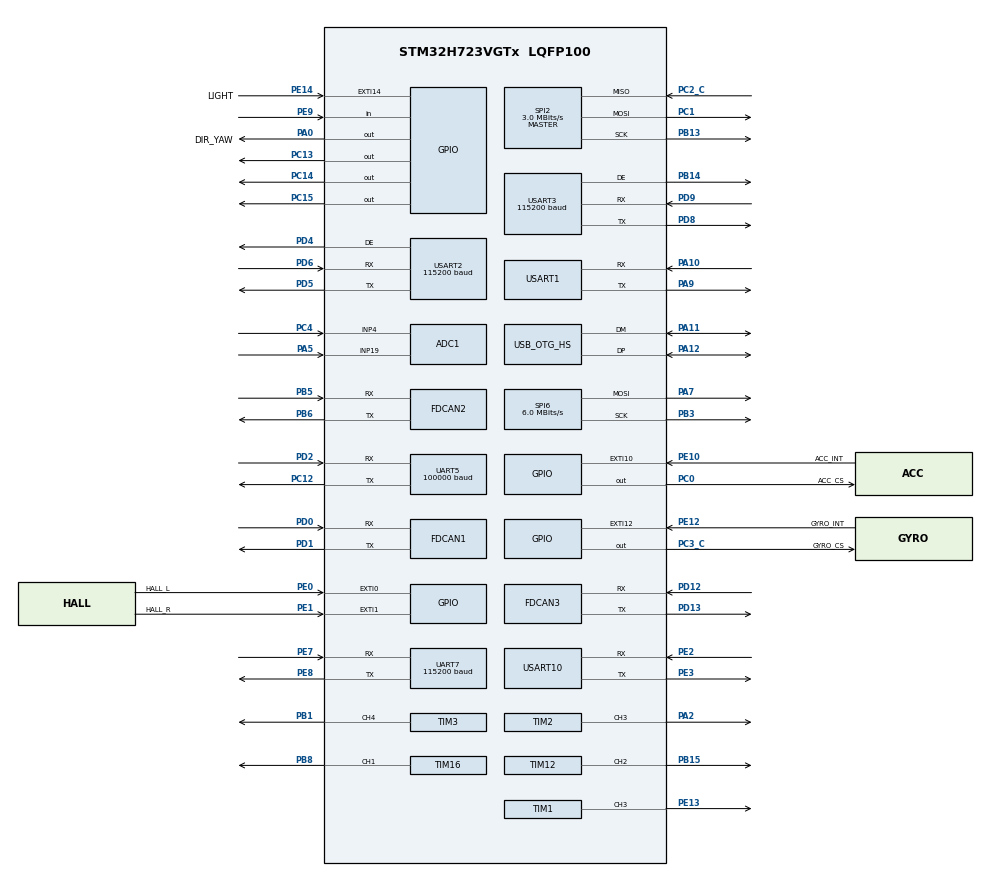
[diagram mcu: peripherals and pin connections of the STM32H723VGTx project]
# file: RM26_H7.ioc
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ADC1.Channel-0\#ChannelRegularConversion=ADC_CHANNEL_4
ADC1.NbrOfConversionFlag=1
ADC1.OffsetNumber-0\#ChannelRegularConversion=ADC_OFFSET_NONE
ADC1.OffsetSignedSaturation-0\#ChannelRegularConversion=DISABLE
ADC1.Rank-0\#ChannelRegularConversion=1
ADC1.SamplingTime-0\#ChannelRegularConversion=ADC_SAMPLETIME_1CYCLE_5
ADC1.master=1
CORTEX_M7.AccessPermission_Spec=MPU_REGION_FULL_ACCESS
CORTEX_M7.BaseAddress_Spec=0x24000000
CORTEX_M7.CPU_DCache=Enabled
CORTEX_M7.CPU_ICache=Enabled
CORTEX_M7.DisableExec_Spec=MPU_INSTRUCTION_ACCESS_ENABLE
CORTEX_M7.IsShareable_Spec=MPU_ACCESS_SHAREABLE
CORTEX_M7.MPU_Control=__NULL
CORTEX_M7.Size_Spec=MPU_REGION_SIZE_512KB
CORTEX_M7.SubRegionDisable_Spec=0x0
CORTEX_M7.TypeExtField_Spec=MPU_TEX_LEVEL1
CORTEX_M7.default_mode_Activation=0
Dma.Request0=USART1_RX
Dma.Request1=USART1_TX
Dma.Request10=USART3_TX
Dma.Request2=UART7_RX
Dma.Request3=UART7_TX
Dma.Request4=UART5_RX
Dma.Request5=USART10_RX
Dma.Request6=USART10_TX
Dma.Request7=USART2_RX
Dma.Request8=USART2_TX
Dma.Request9=USART3_RX
Dma.UART5_RX.4.Direction=DMA_PERIPH_TO_MEMORY
Dma.UART5_RX.4.EventEnable=DISABLE
Dma.UART5_RX.4.FIFOMode=DMA_FIFOMODE_DISABLE
Dma.UART5_RX.4.Instance=DMA2_Stream3
Dma.UART5_RX.4.MemDataAlignment=DMA_MDATAALIGN_BYTE
Dma.UART5_RX.4.MemInc=DMA_MINC_ENABLE
Dma.UART5_RX.4.Mode=DMA_CIRCULAR
Dma.UART5_RX.4.PeriphDataAlignment=DMA_PDATAALIGN_BYTE
Dma.UART5_RX.4.PeriphInc=DMA_PINC_DISABLE
Dma.UART5_RX.4.Polarity=HAL_DMAMUX_REQ_GEN_RISING
Dma.UART5_RX.4.Priority=DMA_PRIORITY_VERY_HIGH
Dma.UART5_RX.4.RequestNumber=1
Dma.UART5_RX.4.SignalID=NONE
Dma.UART5_RX.4.SyncEnable=DISABLE
Dma.UART5_RX.4.SyncPolarity=HAL_DMAMUX_SYNC_NO_EVENT
Dma.UART5_RX.4.SyncRequestNumber=1
Dma.UART5_RX.4.SyncSignalID=NONE
Dma.UART7_RX.2.Direction=DMA_PERIPH_TO_MEMORY
Dma.UART7_RX.2.EventEnable=DISABLE
Dma.UART7_RX.2.FIFOMode=DMA_FIFOMODE_DISABLE
Dma.UART7_RX.2.Instance=DMA1_Stream2
Dma.UART7_RX.2.MemDataAlignment=DMA_MDATAALIGN_BYTE
Dma.UART7_RX.2.MemInc=DMA_MINC_ENABLE
Dma.UART7_RX.2.Mode=DMA_CIRCULAR
Dma.UART7_RX.2.PeriphDataAlignment=DMA_PDATAALIGN_BYTE
Dma.UART7_RX.2.PeriphInc=DMA_PINC_DISABLE
Dma.UART7_RX.2.Polarity=HAL_DMAMUX_REQ_GEN_RISING
Dma.UART7_RX.2.Priority=DMA_PRIORITY_VERY_HIGH
Dma.UART7_RX.2.RequestNumber=1
Dma.UART7_RX.2.SignalID=NONE
Dma.UART7_RX.2.SyncEnable=DISABLE
Dma.UART7_RX.2.SyncPolarity=HAL_DMAMUX_SYNC_NO_EVENT
Dma.UART7_RX.2.SyncRequestNumber=1
Dma.UART7_RX.2.SyncSignalID=NONE
Dma.UART7_TX.3.Direction=DMA_MEMORY_TO_PERIPH
Dma.UART7_TX.3.EventEnable=DISABLE
Dma.UART7_TX.3.FIFOMode=DMA_FIFOMODE_DISABLE
Dma.UART7_TX.3.Instance=DMA1_Stream3
Dma.UART7_TX.3.MemDataAlignment=DMA_MDATAALIGN_BYTE
Dma.UART7_TX.3.MemInc=DMA_MINC_ENABLE
Dma.UART7_TX.3.Mode=DMA_CIRCULAR
Dma.UART7_TX.3.PeriphDataAlignment=DMA_PDATAALIGN_BYTE
Dma.UART7_TX.3.PeriphInc=DMA_PINC_DISABLE
Dma.UART7_TX.3.Polarity=HAL_DMAMUX_REQ_GEN_RISING
Dma.UART7_TX.3.Priority=DMA_PRIORITY_VERY_HIGH
Dma.UART7_TX.3.RequestNumber=1
Dma.UART7_TX.3.SignalID=NONE
Dma.UART7_TX.3.SyncEnable=DISABLE
Dma.UART7_TX.3.SyncPolarity=HAL_DMAMUX_SYNC_NO_EVENT
Dma.UART7_TX.3.SyncRequestNumber=1
Dma.UART7_TX.3.SyncSignalID=NONE
Dma.USART10_RX.5.Direction=DMA_PERIPH_TO_MEMORY
Dma.USART10_RX.5.EventEnable=DISABLE
Dma.USART10_RX.5.FIFOMode=DMA_FIFOMODE_DISABLE
Dma.USART10_RX.5.Instance=DMA1_Stream6
Dma.USART10_RX.5.MemDataAlignment=DMA_MDATAALIGN_BYTE
Dma.USART10_RX.5.MemInc=DMA_MINC_ENABLE
Dma.USART10_RX.5.Mode=DMA_NORMAL
Dma.USART10_RX.5.PeriphDataAlignment=DMA_PDATAALIGN_BYTE
Dma.USART10_RX.5.PeriphInc=DMA_PINC_DISABLE
Dma.USART10_RX.5.Polarity=HAL_DMAMUX_REQ_GEN_RISING
Dma.USART10_RX.5.Priority=DMA_PRIORITY_LOW
Dma.USART10_RX.5.RequestNumber=1
Dma.USART10_RX.5.SignalID=NONE
Dma.USART10_RX.5.SyncEnable=DISABLE
Dma.USART10_RX.5.SyncPolarity=HAL_DMAMUX_SYNC_NO_EVENT
Dma.USART10_RX.5.SyncRequestNumber=1
Dma.USART10_RX.5.SyncSignalID=NONE
Dma.USART10_TX.6.Direction=DMA_MEMORY_TO_PERIPH
Dma.USART10_TX.6.EventEnable=DISABLE
Dma.USART10_TX.6.FIFOMode=DMA_FIFOMODE_DISABLE
Dma.USART10_TX.6.Instance=DMA1_Stream7
Dma.USART10_TX.6.MemDataAlignment=DMA_MDATAALIGN_BYTE
Dma.USART10_TX.6.MemInc=DMA_MINC_ENABLE
Dma.USART10_TX.6.Mode=DMA_NORMAL
Dma.USART10_TX.6.PeriphDataAlignment=DMA_PDATAALIGN_BYTE
Dma.USART10_TX.6.PeriphInc=DMA_PINC_DISABLE
Dma.USART10_TX.6.Polarity=HAL_DMAMUX_REQ_GEN_RISING
Dma.USART10_TX.6.Priority=DMA_PRIORITY_LOW
Dma.USART10_TX.6.RequestNumber=1
Dma.USART10_TX.6.SignalID=NONE
Dma.USART10_TX.6.SyncEnable=DISABLE
Dma.USART10_TX.6.SyncPolarity=HAL_DMAMUX_SYNC_NO_EVENT
Dma.USART10_TX.6.SyncRequestNumber=1
Dma.USART10_TX.6.SyncSignalID=NONE
Dma.USART1_RX.0.Direction=DMA_PERIPH_TO_MEMORY
Dma.USART1_RX.0.EventEnable=DISABLE
Dma.USART1_RX.0.FIFOMode=DMA_FIFOMODE_DISABLE
Dma.USART1_RX.0.Instance=DMA1_Stream4
Dma.USART1_RX.0.MemDataAlignment=DMA_MDATAALIGN_BYTE
Dma.USART1_RX.0.MemInc=DMA_MINC_ENABLE
Dma.USART1_RX.0.Mode=DMA_CIRCULAR
Dma.USART1_RX.0.PeriphDataAlignment=DMA_PDATAALIGN_BYTE
Dma.USART1_RX.0.PeriphInc=DMA_PINC_DISABLE
Dma.USART1_RX.0.Polarity=HAL_DMAMUX_REQ_GEN_RISING
Dma.USART1_RX.0.Priority=DMA_PRIORITY_VERY_HIGH
Dma.USART1_RX.0.RequestNumber=1
Dma.USART1_RX.0.SignalID=NONE
Dma.USART1_RX.0.SyncEnable=DISABLE
Dma.USART1_RX.0.SyncPolarity=HAL_DMAMUX_SYNC_NO_EVENT
Dma.USART1_RX.0.SyncRequestNumber=1
Dma.USART1_RX.0.SyncSignalID=NONE
Dma.USART1_TX.1.Direction=DMA_MEMORY_TO_PERIPH
Dma.USART1_TX.1.EventEnable=DISABLE
Dma.USART1_TX.1.FIFOMode=DMA_FIFOMODE_DISABLE
Dma.USART1_TX.1.Instance=DMA1_Stream5
Dma.USART1_TX.1.MemDataAlignment=DMA_MDATAALIGN_BYTE
Dma.USART1_TX.1.MemInc=DMA_MINC_ENABLE
Dma.USART1_TX.1.Mode=DMA_NORMAL
Dma.USART1_TX.1.PeriphDataAlignment=DMA_PDATAALIGN_BYTE
Dma.USART1_TX.1.PeriphInc=DMA_PINC_DISABLE
Dma.USART1_TX.1.Polarity=HAL_DMAMUX_REQ_GEN_RISING
Dma.USART1_TX.1.Priority=DMA_PRIORITY_VERY_HIGH
Dma.USART1_TX.1.RequestNumber=1
Dma.USART1_TX.1.SignalID=NONE
Dma.USART1_TX.1.SyncEnable=DISABLE
Dma.USART1_TX.1.SyncPolarity=HAL_DMAMUX_SYNC_NO_EVENT
Dma.USART1_TX.1.SyncRequestNumber=1
Dma.USART1_TX.1.SyncSignalID=NONE
Dma.USART2_RX.7.Direction=DMA_PERIPH_TO_MEMORY
Dma.USART2_RX.7.EventEnable=DISABLE
Dma.USART2_RX.7.FIFOMode=DMA_FIFOMODE_DISABLE
Dma.USART2_RX.7.Instance=DMA1_Stream0
Dma.USART2_RX.7.MemDataAlignment=DMA_MDATAALIGN_BYTE
Dma.USART2_RX.7.MemInc=DMA_MINC_ENABLE
Dma.USART2_RX.7.Mode=DMA_NORMAL
Dma.USART2_RX.7.PeriphDataAlignment=DMA_PDATAALIGN_BYTE
Dma.USART2_RX.7.PeriphInc=DMA_PINC_DISABLE
Dma.USART2_RX.7.Polarity=HAL_DMAMUX_REQ_GEN_RISING
Dma.USART2_RX.7.Priority=DMA_PRIORITY_LOW
Dma.USART2_RX.7.RequestNumber=1
Dma.USART2_RX.7.SignalID=NONE
Dma.USART2_RX.7.SyncEnable=DISABLE
Dma.USART2_RX.7.SyncPolarity=HAL_DMAMUX_SYNC_NO_EVENT
Dma.USART2_RX.7.SyncRequestNumber=1
Dma.USART2_RX.7.SyncSignalID=NONE
Dma.USART2_TX.8.Direction=DMA_MEMORY_TO_PERIPH
Dma.USART2_TX.8.EventEnable=DISABLE
Dma.USART2_TX.8.FIFOMode=DMA_FIFOMODE_DISABLE
Dma.USART2_TX.8.Instance=DMA1_Stream1
Dma.USART2_TX.8.MemDataAlignment=DMA_MDATAALIGN_BYTE
Dma.USART2_TX.8.MemInc=DMA_MINC_ENABLE
Dma.USART2_TX.8.Mode=DMA_NORMAL
Dma.USART2_TX.8.PeriphDataAlignment=DMA_PDATAALIGN_BYTE
Dma.USART2_TX.8.PeriphInc=DMA_PINC_DISABLE
Dma.USART2_TX.8.Polarity=HAL_DMAMUX_REQ_GEN_RISING
Dma.USART2_TX.8.Priority=DMA_PRIORITY_LOW
Dma.USART2_TX.8.RequestNumber=1
Dma.USART2_TX.8.SignalID=NONE
Dma.USART2_TX.8.SyncEnable=DISABLE
Dma.USART2_TX.8.SyncPolarity=HAL_DMAMUX_SYNC_NO_EVENT
Dma.USART2_TX.8.SyncRequestNumber=1
Dma.USART2_TX.8.SyncSignalID=NONE
Dma.USART3_RX.9.Direction=DMA_PERIPH_TO_MEMORY
Dma.USART3_RX.9.EventEnable=DISABLE
Dma.USART3_RX.9.FIFOMode=DMA_FIFOMODE_DISABLE
Dma.USART3_RX.9.Instance=DMA2_Stream7
Dma.USART3_RX.9.MemDataAlignment=DMA_MDATAALIGN_BYTE
Dma.USART3_RX.9.MemInc=DMA_MINC_ENABLE
Dma.USART3_RX.9.Mode=DMA_NORMAL
Dma.USART3_RX.9.PeriphDataAlignment=DMA_PDATAALIGN_BYTE
Dma.USART3_RX.9.PeriphInc=DMA_PINC_DISABLE
Dma.USART3_RX.9.Polarity=HAL_DMAMUX_REQ_GEN_RISING
Dma.USART3_RX.9.Priority=DMA_PRIORITY_LOW
Dma.USART3_RX.9.RequestNumber=1
Dma.USART3_RX.9.SignalID=NONE
Dma.USART3_RX.9.SyncEnable=DISABLE
Dma.USART3_RX.9.SyncPolarity=HAL_DMAMUX_SYNC_NO_EVENT
Dma.USART3_RX.9.SyncRequestNumber=1
Dma.USART3_RX.9.SyncSignalID=NONE
Dma.USART3_TX.10.Direction=DMA_MEMORY_TO_PERIPH
Dma.USART3_TX.10.EventEnable=DISABLE
Dma.USART3_TX.10.FIFOMode=DMA_FIFOMODE_DISABLE
Dma.USART3_TX.10.Instance=DMA2_Stream6
Dma.USART3_TX.10.MemDataAlignment=DMA_MDATAALIGN_BYTE
Dma.USART3_TX.10.MemInc=DMA_MINC_ENABLE
Dma.USART3_TX.10.Mode=DMA_NORMAL
Dma.USART3_TX.10.PeriphDataAlignment=DMA_PDATAALIGN_BYTE
Dma.USART3_TX.10.PeriphInc=DMA_PINC_DISABLE
Dma.USART3_TX.10.Polarity=HAL_DMAMUX_REQ_GEN_RISING
Dma.USART3_TX.10.Priority=DMA_PRIORITY_LOW
Dma.USART3_TX.10.RequestNumber=1
Dma.USART3_TX.10.SignalID=NONE
Dma.USART3_TX.10.SyncEnable=DISABLE
Dma.USART3_TX.10.SyncPolarity=HAL_DMAMUX_SYNC_NO_EVENT
Dma.USART3_TX.10.SyncRequestNumber=1
Dma.USART3_TX.10.SyncSignalID=NONE
FDCAN1.CalculateBaudRateNominal=1000000
FDCAN1.CalculateTimeBitNominal=1000
FDCAN1.CalculateTimeQuantumNominal=166.66666666666666
FDCAN1.DataPrescaler=4
FDCAN1.DataSyncJumpWidth=1
FDCAN1.DataTimeSeg1=3
FDCAN1.DataTimeSeg2=2
FDCAN1.NominalPrescaler=4
FDCAN1.NominalSyncJumpWidth=1
FDCAN1.NominalTimeSeg1=3
FDCAN1.NominalTimeSeg2=2
FDCAN1.ProtocolException=ENABLE
FDCAN1.RxFifo0ElmtsNbr=4
FDCAN1.StdFiltersNbr=1
FDCAN1.TxEventsNbr=0
FDCAN1.TxFifoQueueElmtsNbr=2
FDCAN2.CalculateBaudRateNominal=1000000
FDCAN2.CalculateTimeBitNominal=1000
FDCAN2.CalculateTimeQuantumNominal=166.66666666666666
FDCAN2.DataPrescaler=4
FDCAN2.DataSyncJumpWidth=1
FDCAN2.DataTimeSeg1=3
FDCAN2.DataTimeSeg2=2
FDCAN2.MessageRAMOffset=853
FDCAN2.NominalPrescaler=4
FDCAN2.NominalSyncJumpWidth=1
FDCAN2.NominalTimeSeg1=3
FDCAN2.NominalTimeSeg2=2
FDCAN2.ProtocolException=ENABLE
FDCAN2.RxFifo0ElmtsNbr=8
FDCAN2.StdFiltersNbr=1
FDCAN2.TxFifoQueueElmtsNbr=8
FDCAN3.CalculateBaudRateNominal=1000000
FDCAN3.CalculateTimeBitNominal=1000
FDCAN3.CalculateTimeQuantumNominal=166.66666666666666
FDCAN3.DataPrescaler=4
FDCAN3.DataSyncJumpWidth=1
FDCAN3.DataTimeSeg1=3
FDCAN3.DataTimeSeg2=2
FDCAN3.ExtFiltersNbr=1
FDCAN3.MessageRAMOffset=1706
FDCAN3.NominalPrescaler=4
FDCAN3.NominalSyncJumpWidth=1
FDCAN3.NominalTimeSeg1=3
FDCAN3.NominalTimeSeg2=2
FDCAN3.ProtocolException=ENABLE
FDCAN3.RxFifo0ElmtsNbr=16
FDCAN3.StdFiltersNbr=1
FDCAN3.TxFifoQueueElmtsNbr=16
Mcu.Family=STM32H7
Mcu.Name=STM32H723VGTx
Mcu.Package=LQFP100
NVIC.DMA1_Stream0_IRQn=true\:0\:0\:false\:false\:true\:true\:false\:true\:true
NVIC.DMA1_Stream1_IRQn=true\:0\:0\:false\:false\:true\:true\:false\:true\:true
NVIC.DMA1_Stream2_IRQn=true\:0\:0\:false\:false\:true\:false\:false\:true\:true
NVIC.DMA1_Stream3_IRQn=true\:0\:0\:false\:false\:true\:false\:false\:true\:true
NVIC.DMA1_Stream4_IRQn=true\:0\:0\:false\:false\:true\:false\:false\:true\:true
NVIC.DMA1_Stream5_IRQn=true\:0\:0\:false\:false\:true\:false\:false\:true\:true
NVIC.DMA1_Stream6_IRQn=true\:0\:0\:false\:false\:true\:true\:false\:true\:true
NVIC.DMA1_Stream7_IRQn=true\:0\:0\:false\:false\:true\:true\:false\:true\:true
NVIC.DMA2_Stream3_IRQn=true\:0\:0\:false\:false\:true\:false\:false\:true\:true
NVIC.DMA2_Stream6_IRQn=true\:0\:0\:false\:false\:true\:false\:false\:true\:true
NVIC.DMA2_Stream7_IRQn=true\:0\:0\:false\:false\:true\:false\:false\:true\:true
NVIC.EXTI0_IRQn=true\:0\:0\:false\:false\:true\:false\:true\:true\:true
NVIC.EXTI15_10_IRQn=true\:0\:0\:false\:false\:true\:false\:true\:true\:true
NVIC.EXTI1_IRQn=true\:0\:0\:false\:false\:true\:false\:true\:true\:true
NVIC.FDCAN1_IT0_IRQn=true\:0\:0\:false\:false\:true\:false\:true\:true\:true
NVIC.FDCAN2_IT0_IRQn=true\:0\:0\:false\:false\:true\:false\:true\:true\:true
NVIC.FDCAN3_IT0_IRQn=true\:0\:0\:false\:false\:true\:false\:true\:true\:true
NVIC.OTG_HS_IRQn=true\:0\:0\:false\:false\:true\:false\:true\:true\:true
NVIC.PriorityGroup=NVIC_PRIORITYGROUP_4
NVIC.TIM23_IRQn=true\:15\:0\:false\:false\:true\:false\:false\:true\:true
NVIC.TIM2_IRQn=true\:0\:0\:false\:false\:true\:false\:true\:true\:true
NVIC.TIM5_IRQn=true\:0\:0\:false\:false\:true\:false\:true\:true\:true
NVIC.TimeBase=TIM23_IRQn
NVIC.TimeBaseIP=TIM23
NVIC.UART5_IRQn=true\:0\:0\:false\:false\:true\:false\:true\:true\:true
NVIC.UART7_IRQn=true\:0\:0\:false\:false\:true\:false\:true\:true\:true
NVIC.USART10_IRQn=true\:0\:0\:false\:false\:true\:false\:true\:true\:true
NVIC.USART1_IRQn=true\:0\:0\:false\:false\:true\:false\:true\:true\:true
NVIC.USART2_IRQn=true\:0\:0\:false\:false\:true\:false\:true\:true\:true
NVIC.USART3_IRQn=true\:0\:0\:false\:false\:true\:false\:true\:true\:true
PA0.GPIO_Label=DIR_YAW
PA0.GPIO_ModeDefaultOutputPP=GPIO_MODE_OUTPUT_OD
PA0.GPIO_PuPd=GPIO_NOPULL
PA0.Signal=GPIO_Output
PA10.Mode=Asynchronous
PA10.Signal=USART1_RX
PA11.Mode=Device_Only_FS
PA11.Signal=USB_OTG_HS_DM
PA12.Mode=Device_Only_FS
PA12.Signal=USB_OTG_HS_DP
PA2.Signal=S_TIM2_CH3
PA5.Signal=ADCx_INP19
PA7.Mode=TX_Only_Simplex_Unidirect_Master
PA7.Signal=SPI6_MOSI
PA9.Mode=Asynchronous
PA9.Signal=USART1_TX
PB1.Signal=S_TIM3_CH4
PB13.GPIO_Speed=GPIO_SPEED_FREQ_VERY_HIGH
PB13.Mode=Full_Duplex_Master
PB13.Signal=SPI2_SCK
PB14.Mode=Hardware Flow Control (RS485)
PB14.Signal=USART3_DE
PB15.Signal=S_TIM12_CH2
PB3(JTDO/TRACESWO).Mode=TX_Only_Simplex_Unidirect_Master
PB3(JTDO/TRACESWO).Signal=SPI6_SCK
PB5.Mode=FDCAN_Activate
PB5.Signal=FDCAN2_RX
PB6.Mode=FDCAN_Activate
PB6.Signal=FDCAN2_TX
PB8.Signal=S_TIM16_CH1
PC0.GPIO_Label=ACC_CS
PC0.GPIO_Speed=GPIO_SPEED_FREQ_VERY_HIGH
PC0.PinState=GPIO_PIN_SET
PC0.Signal=GPIO_Output
PC1.GPIO_Speed=GPIO_SPEED_FREQ_VERY_HIGH
PC1.Mode=Full_Duplex_Master
PC1.Signal=SPI2_MOSI
PC12.Mode=Asynchronous
PC12.Signal=UART5_TX
PC13.PinState=GPIO_PIN_SET
PC13.Signal=GPIO_Output
PC14-OSC32_IN.PinState=GPIO_PIN_SET
PC14-OSC32_IN.Signal=GPIO_Output
PC15-OSC32_OUT.PinState=GPIO_PIN_SET
PC15-OSC32_OUT.Signal=GPIO_Output
PC2_C.GPIO_Speed=GPIO_SPEED_FREQ_VERY_HIGH
PC2_C.Mode=Full_Duplex_Master
PC2_C.Signal=SPI2_MISO
PC3_C.GPIO_Label=GYRO_CS
PC3_C.GPIO_Speed=GPIO_SPEED_FREQ_VERY_HIGH
PC3_C.PinState=GPIO_PIN_SET
PC3_C.Signal=GPIO_Output
PC4.Signal=ADCx_INP4
PD0.Mode=FDCAN_Activate
PD0.Signal=FDCAN1_RX
PD1.Mode=FDCAN_Activate
PD1.Signal=FDCAN1_TX
PD12.Mode=FDCAN_Activate
PD12.Signal=FDCAN3_RX
PD13.Mode=FDCAN_Activate
PD13.Signal=FDCAN3_TX
PD2.GPIO_Speed=GPIO_SPEED_FREQ_LOW
PD2.Mode=Asynchronous
PD2.Signal=UART5_RX
PD4.Mode=Hardware Flow Control (RS485)
PD4.Signal=USART2_DE
PD5.Mode=Asynchronous
PD5.Signal=USART2_TX
PD6.Mode=Asynchronous
PD6.Signal=USART2_RX
PD8.Mode=Asynchronous
PD8.Signal=USART3_TX
PD9.Mode=Asynchronous
PD9.Signal=USART3_RX
PE0.GPIO_Label=HALL_L
PE0.GPIO_ModeDefaultEXTI=GPIO_MODE_IT_FALLING
PE0.GPIO_PuPd=GPIO_PULLUP
PE0.Signal=GPXTI0
PE1.GPIO_Label=HALL_R
PE1.GPIO_ModeDefaultEXTI=GPIO_MODE_IT_FALLING
PE1.Signal=GPXTI1
PE10.GPIO_Label=ACC_INT
PE10.Signal=GPXTI10
PE12.GPIO_Label=GYRO_INT
PE12.Signal=GPXTI12
PE13.Signal=S_TIM1_CH3
PE14.GPIO_Label=LIGHT
PE14.GPIO_ModeDefaultEXTI=GPIO_MODE_IT_FALLING
PE14.Signal=GPXTI14
PE2.Mode=Asynchronous
PE2.Signal=USART10_RX
PE3.Mode=Asynchronous
PE3.Signal=USART10_TX
PE7.Mode=Asynchronous
PE7.Signal=UART7_RX
PE8.Mode=Asynchronous
PE8.Signal=UART7_TX
PE9.GPIO_PuPd=GPIO_PULLUP
PE9.Signal=GPIO_Input
PH0-OSC_IN.Mode=HSE-External-Oscillator
PH0-OSC_IN.Signal=RCC_OSC_IN
PH1-OSC_OUT.Mode=HSE-External-Oscillator
PH1-OSC_OUT.Signal=RCC_OSC_OUT
ProjectManager.HeapSize=0x4000
ProjectManager.StackSize=0x4500
ProjectManager.TargetToolchain=CMake
RCC.ADCFreq_Value=48000000
RCC.APB1Freq_Value=96000000
RCC.APB2Freq_Value=96000000
RCC.APB3Freq_Value=96000000
RCC.APB4Freq_Value=96000000
RCC.CortexFreq_Value=192000000
RCC.D1PPRE=RCC_APB3_DIV2
RCC.D2PPRE1=RCC_APB1_DIV2
RCC.D2PPRE2=RCC_APB2_DIV2
RCC.D3PPRE=RCC_APB4_DIV2
RCC.DIVM1=2
RCC.DIVM2=2
RCC.DIVM3=2
RCC.DIVN1=16
RCC.DIVN2=16
RCC.DIVN3=16
RCC.DIVP1=1
RCC.DIVP2=4
RCC.DIVQ1=4
RCC.FDCANCLockSelection=RCC_FDCANCLKSOURCE_HSE
RCC.HCLKFreq_Value=192000000
RCC.HSE_VALUE=24000000
RCC.PLL2FRACN=0
RCC.PLLFRACN=0
RCC.PLLSourceVirtual=RCC_PLLSOURCE_HSE
RCC.SPI123CLockSelection=RCC_SPI123CLKSOURCE_PLL
RCC.SPI6CLockSelection=RCC_SPI6CLKSOURCE_HSE
RCC.SYSCLKFreq_VALUE=192000000
RCC.SYSCLKSource=RCC_SYSCLKSOURCE_PLLCLK
RCC.USBFreq_Value=48000000
SH.ADCx_INP19.0=ADC1_INP19,IN19-Single-Ended
SH.ADCx_INP4.0=ADC1_INP4,IN4-Single-Ended
SH.S_TIM12_CH2.0=TIM12_CH2,PWM Generation2 CH2
SH.S_TIM16_CH1.0=TIM16_CH1,PWM Generation1 CH1
SH.S_TIM1_CH3.0=TIM1_CH3,PWM Generation3 CH3
SH.S_TIM2_CH3.0=TIM2_CH3,PWM Generation3 CH3
SH.S_TIM3_CH4.0=TIM3_CH4,PWM Generation4 CH4
SPI2.BaudRatePrescaler=SPI_BAUDRATEPRESCALER_16
SPI2.CLKPhase=SPI_PHASE_2EDGE
SPI2.CLKPolarity=SPI_POLARITY_HIGH
SPI2.CalculateBaudRate=3.0 MBits/s
SPI2.DataSize=SPI_DATASIZE_8BIT
SPI2.Direction=SPI_DIRECTION_2LINES
SPI2.Mode=SPI_MODE_MASTER
SPI2.NSSPMode=SPI_NSS_PULSE_DISABLE
SPI2.VirtualType=VM_MASTER
SPI6.BaudRatePrescaler=SPI_BAUDRATEPRESCALER_4
SPI6.CLKPhase=SPI_PHASE_2EDGE
SPI6.CalculateBaudRate=6.0 MBits/s
SPI6.DataSize=SPI_DATASIZE_8BIT
SPI6.Direction=SPI_DIRECTION_2LINES_TXONLY
SPI6.Mode=SPI_MODE_MASTER
SPI6.VirtualType=VM_MASTER
STMicroelectronics.X-CUBE-ALGOBUILD.1.4.0.LibraryCcDSPOoLibraryJjDSPOoLibrary=true
STMicroelectronics.X-CUBE-AZRTOS-H7.3.4.0.TX_DISABLE_ERROR_CHECKING=1
STMicroelectronics.X-CUBE-AZRTOS-H7.3.4.0.TX_DISABLE_REDUNDANT_CLEARING=1
STMicroelectronics.X-CUBE-AZRTOS-H7.3.4.0.TX_DISABLE_STACK_FILLING=1
STMicroelectronics.X-CUBE-AZRTOS-H7.3.4.0.TX_INLINE_THREAD_RESUME_SUSPEND=1
STMicroelectronics.X-CUBE-AZRTOS-H7.3.4.0.TX_NOT_INTERRUPTABLE=1
STMicroelectronics.X-CUBE-AZRTOS-H7.3.4.0.TX_REACTIVATE_INLINE=1
STMicroelectronics.X-CUBE-AZRTOS-H7.3.4.0.TX_TIMER_PROCESS_IN_ISR=1
STMicroelectronics.X-CUBE-AZRTOS-H7.3.4.0.TX_TIMER_TICKS_PER_SECOND=1000
STMicroelectronics.X-CUBE-AZRTOS-H7.3.4.0.ThreadXCcRTOSJjThreadXJjCore=true
STMicroelectronics.X-CUBE-AZRTOS-H7.3.4.0.USBD_CDCACM_EPINCMD_ADDR=2
STMicroelectronics.X-CUBE-AZRTOS-H7.3.4.0.USBD_PRODUCT_STRING=Doraemon
STMicroelectronics.X-CUBE-AZRTOS-H7.3.4.0.USBD_SERIAL_NUMBER=LXYPIG
STMicroelectronics.X-CUBE-AZRTOS-H7.3.4.0.USBXCcUSBJjUSBXJjCoreSystem=true
STMicroelectronics.X-CUBE-AZRTOS-H7.3.4.0.USBXCcUSBJjUSBXJjUXOoDeviceOoClassOoCDCOoACM=true
STMicroelectronics.X-CUBE-AZRTOS-H7.3.4.0.USBXCcUSBJjUSBXJjUXOoDeviceOoControllers=true
STMicroelectronics.X-CUBE-AZRTOS-H7.3.4.0.USBXCcUSBJjUSBXJjUXOoDeviceOoCoreStack=true
STMicroelectronics.X-CUBE-AZRTOS-H7.3.4.0.USBX_DEVICE_SYS_SIZE=7*1024
STMicroelectronics.X-CUBE-AZRTOS-H7.3.4.0.UX_DEVICE_APP_MEM_POOL_SIZE=12*1024
STMicroelectronics.X-CUBE-AZRTOS-H7.3.4.0.UX_DEVICE_SIDE_ONLY=1
STMicroelectronics.X-CUBE-AZRTOS-H7.3.4.0.UX_SLAVE_REQUEST_DATA_MAX_LENGTH=512
STMicroelectronics.X-CUBE-AZRTOS-H7.3.4.0.UX_THREAD_STACK_SIZE=2048
STMicroelectronics.X-CUBE-AZRTOS-H7.3.4.0_IsAnAzureRtosMw=true
TIM1.AutoReloadPreload=TIM_AUTORELOAD_PRELOAD_ENABLE
TIM1.Channel-PWM\ Generation3\ CH3=TIM_CHANNEL_3
TIM1.Period=20000-1
TIM1.Prescaler=192-1
TIM12.Channel-PWM\ Generation2\ CH2=TIM_CHANNEL_2
TIM12.Period=2000-1
TIM12.Prescaler=24-1
TIM12.Pulse-PWM\ Generation2\ CH2=1000
TIM16.Channel=TIM_CHANNEL_1
TIM16.Period=20000-1
TIM16.Prescaler=192-1
TIM2.AutoReloadPreload=TIM_AUTORELOAD_PRELOAD_ENABLE
TIM2.Channel-PWM\ Generation3\ CH3=TIM_CHANNEL_3
TIM2.OCPolarity_3=TIM_OCPOLARITY_LOW
TIM2.Period=2000-1
TIM2.Prescaler=192-1
TIM2.TIM_MasterOutputTrigger=TIM_TRGO_UPDATE
TIM2.TIM_MasterSlaveMode=TIM_MASTERSLAVEMODE_ENABLE
TIM24.AutoReloadPreload=TIM_AUTORELOAD_PRELOAD_ENABLE
TIM3.Channel-PWM\ Generation4\ CH4=TIM_CHANNEL_4
TIM3.Period=10000-1
TIM3.Prescaler=24-1
TIM4.AutoReloadPreload=TIM_AUTORELOAD_PRELOAD_ENABLE
TIM4.Period=2000-1
TIM4.Prescaler=192-1
TIM4.TIM_MasterOutputTrigger=TIM_TRGO_UPDATE
TIM4.TIM_MasterSlaveMode=TIM_MASTERSLAVEMODE_ENABLE
TIM5.AutoReloadPreload=TIM_AUTORELOAD_PRELOAD_ENABLE
UART5.BaudRate=100000
UART5.Mode=MODE_RX
UART5.StopBits=UART_STOPBITS_2
UART5.WordLength=WORDLENGTH_9B
UART7.BaudRate=115200
USART1.VirtualMode-Asynchronous=VM_ASYNC
USART10.VirtualMode=VM_ASYNC
USART2.BaudRate=115200
USART2.OverSampling=UART_OVERSAMPLING_8
USART2.VirtualMode-Asynchronous=VM_ASYNC
USART2.VirtualMode-Hardware\ Flow\ Control\ (RS485)=VM_ASYNC
USART3.BaudRate=115200
USART3.OverSampling=UART_OVERSAMPLING_8
USART3.VirtualMode-Asynchronous=VM_ASYNC
USART3.VirtualMode-Hardware\ Flow\ Control\ (RS485)=VM_ASYNC
USB_OTG_HS.VirtualMode-Device_Only_FS=Device_Only_FS
VP_CRC_VS_CRC.Mode=CRC_Activate
VP_MEMORYMAP_VS_MEMORYMAP.Mode=CurAppReg
VP_STMicroelectronics.X-CUBE-ALGOBUILD_VS_DSPOoLibraryJjLibrary_1.4.0_1.4.0.Mode=DSPOoLibraryJjLibrary
VP_STMicroelectronics.X-CUBE-AZRTOS-H7_VS_RTOSJjThreadX_6.4.0_3.4.0.Mode=RTOSJjThreadX
VP_STMicroelectronics.X-CUBE-AZRTOS-H7_VS_USBJjUSBX_6.4.0_3.4.0.Mode=USBJjUSBX
VP_SYS_VS_tim23.Mode=TIM23
VP_TIM16_VS_ClockSourceINT.Mode=Enable_Timer
VP_TIM1_VS_ClockSourceINT.Mode=Internal
VP_TIM24_VS_ClockSourceITR.Mode=TriggerSource_ITR1
VP_TIM24_VS_ControllerModeClock.Mode=Clock Mode
VP_TIM2_VS_ClockSourceINT.Mode=Internal
VP_TIM4_VS_ClockSourceINT.Mode=Internal
VP_TIM5_VS_ClockSourceITR.Mode=TriggerSource_ITR3
VP_TIM5_VS_ControllerModeClock.Mode=Clock Mode
board=custom

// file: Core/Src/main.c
/* USER CODE BEGIN Header */
/**
  ******************************************************************************
  * @file           : main.c
  * @brief          : Main program body
  ******************************************************************************
  * @attention
  *
  * Copyright (c) 2025 STMicroelectronics.
  * All rights reserved.
  *
  * This software is licensed under terms that can be found in the LICENSE file
  * in the root directory of this software component.
  * If no LICENSE file comes with this software, it is provided AS-IS.
  *
  ******************************************************************************
  */
/* USER CODE END Header */
#include "app_threadx.h"
#include "main.h"
#include "adc.h"
#include "crc.h"
#include "dma.h"
#include "fdcan.h"
#include "spi.h"
#include "tim.h"
#include "usart.h"
#include "usb_otg.h"
#include "gpio.h"

/* USER CODE BEGIN Includes */
#include "bsp.hpp"
/* USER CODE END Includes */

void SystemClock_Config(void);

int main(void)
{

  /* Enable the CPU Cache */

  /* Enable I-Cache---------------------------------------------------------*/
  SCB_EnableICache();

  /* Enable D-Cache---------------------------------------------------------*/
  SCB_EnableDCache();

  /* MCU Configuration--------------------------------------------------------*/

  /* Reset of all peripherals, Initializes the Flash interface and the Systick. */
  HAL_Init();

  /* Configure the system clock */
  SystemClock_Config();

  /* Initialize all configured peripherals */
  MX_GPIO_Init();
  MX_DMA_Init();
  MX_FDCAN1_Init();
  MX_FDCAN2_Init();
  MX_FDCAN3_Init();
  MX_USART1_UART_Init();
  MX_ADC1_Init();
  MX_SPI2_Init();
  MX_SPI6_Init();
  MX_TIM12_Init();
  MX_UART7_Init();
  MX_TIM3_Init();
  MX_TIM2_Init();
  MX_CRC_Init();
  MX_USB_OTG_HS_PCD_Init();
  MX_TIM1_Init();
  MX_TIM4_Init();
  MX_TIM5_Init();
  MX_TIM24_Init();
  MX_UART5_Init();
  MX_USART10_UART_Init();
  MX_USART2_UART_Init();
  MX_USART3_UART_Init();
  MX_TIM16_Init();
  /* USER CODE BEGIN 2 */
  bsp_Init();
  /* USER CODE END 2 */

  MX_ThreadX_Init();

  /* We should never get here as control is now taken by the scheduler */

  /* Infinite loop */
  while (1)
  {

  }
}

void SystemClock_Config(void)
{
  RCC_OscInitTypeDef RCC_OscInitStruct = {0};
  RCC_ClkInitTypeDef RCC_ClkInitStruct = {0};

  /** Supply configuration update enable
  */
  HAL_PWREx_ConfigSupply(PWR_LDO_SUPPLY);

  /** Configure the main internal regulator output voltage
  */
  __HAL_PWR_VOLTAGESCALING_CONFIG(PWR_REGULATOR_VOLTAGE_SCALE1);

  while(!__HAL_PWR_GET_FLAG(PWR_FLAG_VOSRDY)) {}

  /** Initializes the RCC Oscillators according to the specified parameters
  * in the RCC_OscInitTypeDef structure.
  */
  RCC_OscInitStruct.OscillatorType = RCC_OSCILLATORTYPE_HSE;
  RCC_OscInitStruct.HSEState = RCC_HSE_ON;
  RCC_OscInitStruct.PLL.PLLState = RCC_PLL_ON;
  RCC_OscInitStruct.PLL.PLLSource = RCC_PLLSOURCE_HSE;
  RCC_OscInitStruct.PLL.PLLM = 2;
  RCC_OscInitStruct.PLL.PLLN = 16;
  RCC_OscInitStruct.PLL.PLLP = 1;
  RCC_OscInitStruct.PLL.PLLQ = 4;
  RCC_OscInitStruct.PLL.PLLR = 2;
  RCC_OscInitStruct.PLL.PLLRGE = RCC_PLL1VCIRANGE_3;
  RCC_OscInitStruct.PLL.PLLVCOSEL = RCC_PLL1VCOWIDE;
  RCC_OscInitStruct.PLL.PLLFRACN = 0;
  if (HAL_RCC_OscConfig(&RCC_OscInitStruct) != HAL_OK)
  {
    Error_Handler();
  }

  /** Initializes the CPU, AHB and APB buses clocks
  */
  RCC_ClkInitStruct.ClockType = RCC_CLOCKTYPE_HCLK|RCC_CLOCKTYPE_SYSCLK
                              |RCC_CLOCKTYPE_PCLK1|RCC_CLOCKTYPE_PCLK2
                              |RCC_CLOCKTYPE_D3PCLK1|RCC_CLOCKTYPE_D1PCLK1;
  RCC_ClkInitStruct.SYSCLKSource = RCC_SYSCLKSOURCE_PLLCLK;
  RCC_ClkInitStruct.SYSCLKDivider = RCC_SYSCLK_DIV1;
  RCC_ClkInitStruct.AHBCLKDivider = RCC_HCLK_DIV1;
  RCC_ClkInitStruct.APB3CLKDivider = RCC_APB3_DIV2;
  RCC_ClkInitStruct.APB1CLKDivider = RCC_APB1_DIV2;
  RCC_ClkInitStruct.APB2CLKDivider = RCC_APB2_DIV2;
  RCC_ClkInitStruct.APB4CLKDivider = RCC_APB4_DIV2;

  if (HAL_RCC_ClockConfig(&RCC_ClkInitStruct, FLASH_LATENCY_2) != HAL_OK)
  {
    Error_Handler();
  }
}

void HAL_TIM_PeriodElapsedCallback(TIM_HandleTypeDef *htim)
{
  if (htim->Instance == TIM23)
  {
    HAL_IncTick();
  }
}

void Error_Handler(void)
{
  __disable_irq();
  while (1)
  {
  }
}
